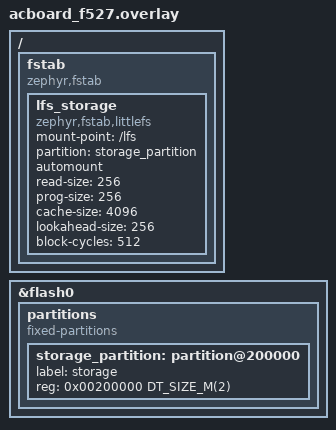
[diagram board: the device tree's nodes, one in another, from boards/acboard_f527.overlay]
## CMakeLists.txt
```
# SPDX-License-Identifier: Apache-2.0

cmake_minimum_required(VERSION 3.20.0)

find_package(Zephyr REQUIRED HINTS $ENV{ZEPHYR_BASE})
project(acboard_littlefs_config)

target_sources(app PRIVATE src/main.c)
```

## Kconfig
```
# Copyright (c) 2026
# SPDX-License-Identifier: Apache-2.0

mainmenu "ACBoard LittleFS config storage"

source "Kconfig.zephyr"
```

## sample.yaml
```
sample:
  name: ACBoard LittleFS config storage
common:
  platform_allow:
    - acboard_f527
  tags:
    - filesystem
    - flash
tests:
  sample.boards.acboard.littlefs_config:
    build_only: true
```

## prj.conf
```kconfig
CONFIG_FLASH=y
CONFIG_FLASH_MAP=y

CONFIG_FILE_SYSTEM=y
CONFIG_FILE_SYSTEM_LITTLEFS=y
CONFIG_FS_LITTLEFS_FSTAB_AUTOMOUNT=y

# The per-file cache heap is sized from this Kconfig; it must match the fstab
# cache-size (4096) or fs_open() fails with -ENOMEM.
CONFIG_FS_LITTLEFS_CACHE_SIZE=4096

CONFIG_PRINTK=y
CONFIG_LOG=y

# fs_dirent / LittleFS caches are sizeable.
CONFIG_MAIN_STACK_SIZE=4096
```

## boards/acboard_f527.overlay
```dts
/ {
	fstab {
		compatible = "zephyr,fstab";

		lfs_storage: lfs_storage {
			compatible = "zephyr,fstab,littlefs";
			mount-point = "/lfs";
			partition = <&storage_partition>;
			automount;
			/*
			 * Bank1 erase blocks are 128KB. read/prog/cache/lookahead
			 * must all divide the block size evenly.
			 */
			read-size = <256>;
			prog-size = <256>;
			cache-size = <4096>;
			lookahead-size = <256>;
			block-cycles = <512>;
		};
	};
};

/*
 * Bank1 (0x200000-0x3FFFFF, 2MB) is reserved as configuration storage. The
 * first erase block (128KB) is physically the group 4x16KB + 64KB, which sums
 * to exactly 128KB, so a uniform 128KB LittleFS block aligns across the whole
 * bank.
 */
&flash0 {
	partitions {
		compatible = "fixed-partitions";
		#address-cells = <1>;
		#size-cells = <1>;

		storage_partition: partition@200000 {
			label = "storage";
			reg = <0x00200000 DT_SIZE_M(2)>;
		};
	};
};
```

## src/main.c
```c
/*
 * Copyright (c) 2026
 * SPDX-License-Identifier: Apache-2.0
 *
 * Demonstrates LittleFS configuration storage on the GD32F527 Bank1 flash
 * (2MB) of ACBoard-F527. The filesystem is auto-mounted at /lfs by the fstab
 * entry. The sample keeps a persistent boot counter and a small key-value
 * config file to show that data survives resets and power cycles.
 */

#include <errno.h>
#include <stdint.h>
#include <stdio.h>
#include <string.h>

#include <zephyr/fs/fs.h>
#include <zephyr/kernel.h>
#include <zephyr/sys/printk.h>

#define MOUNT_POINT	"/lfs"
#define COUNTER_PATH	MOUNT_POINT "/boot_count"
#define CONFIG_PATH	MOUNT_POINT "/device.cfg"

static int read_boot_count(uint32_t *count)
{
	struct fs_file_t file;
	int ret;

	fs_file_t_init(&file);
	*count = 0U;

	ret = fs_open(&file, COUNTER_PATH, FS_O_CREATE | FS_O_RDWR);
	if (ret < 0) {
		printk("open %s failed: %d\n", COUNTER_PATH, ret);
		return ret;
	}

	ret = fs_read(&file, count, sizeof(*count));
	if (ret < 0) {
		printk("read boot count failed: %d\n", ret);
		(void)fs_close(&file);
		return ret;
	}
	if (ret < (int)sizeof(*count)) {
		/* Fresh file. */
		*count = 0U;
	}

	(void)fs_close(&file);
	return 0;
}

static int write_boot_count(uint32_t count)
{
	struct fs_file_t file;
	int ret;

	fs_file_t_init(&file);

	ret = fs_open(&file, COUNTER_PATH, FS_O_CREATE | FS_O_RDWR);
	if (ret < 0) {
		return ret;
	}

	ret = fs_seek(&file, 0, FS_SEEK_SET);
	if (ret == 0) {
		ret = fs_write(&file, &count, sizeof(count));
	}

	(void)fs_close(&file);
	return (ret < 0) ? ret : 0;
}

static int store_config(const char *text)
{
	struct fs_file_t file;
	int ret;

	fs_file_t_init(&file);

	ret = fs_open(&file, CONFIG_PATH, FS_O_CREATE | FS_O_WRITE | FS_O_TRUNC);
	if (ret < 0) {
		return ret;
	}

	ret = fs_write(&file, text, strlen(text));
	(void)fs_close(&file);
	return (ret < 0) ? ret : 0;
}

static int load_config(char *buf, size_t buf_size)
{
	struct fs_file_t file;
	int ret;

	fs_file_t_init(&file);

	ret = fs_open(&file, CONFIG_PATH, FS_O_READ);
	if (ret < 0) {
		return ret;
	}

	ret = fs_read(&file, buf, buf_size - 1U);
	if (ret >= 0) {
		buf[ret] = '\0';
	}
	(void)fs_close(&file);
	return ret;
}

int main(void)
{
	struct fs_statvfs stat;
	char config[64];
	uint32_t boot_count;
	int ret;

	printk("\nACBoard GD32F527 LittleFS config storage (Bank1, 2MB)\n");

	ret = fs_statvfs(MOUNT_POINT, &stat);
	if (ret < 0) {
		printk("%s not mounted: %d\n", MOUNT_POINT, ret);
		return 0;
	}
	printk("%s mounted: block size %lu, blocks %lu, free %lu\n", MOUNT_POINT,
	       stat.f_bsize, stat.f_blocks, stat.f_bfree);

	ret = read_boot_count(&boot_count);
	if (ret < 0) {
		return 0;
	}
	boot_count++;
	printk("boot count: %u\n", boot_count);

	ret = write_boot_count(boot_count);
	if (ret < 0) {
		printk("persist boot count failed: %d\n", ret);
		return 0;
	}

	/* On the first boot store an example device config; afterwards read it
	 * back to prove persistence.
	 */
	struct fs_dirent ent;

	ret = fs_stat(CONFIG_PATH, &ent);
	if (ret == -ENOENT) {
		const char *initial = "name=ID.UNYX;pnc=1";

		printk("no config yet, writing defaults\n");
		ret = store_config(initial);
		if (ret < 0) {
			printk("store config failed: %d\n", ret);
			return 0;
		}
		strcpy(config, initial);
	} else if (ret == 0) {
		ret = load_config(config, sizeof(config));
		if (ret < 0) {
			printk("load config failed: %d\n", ret);
			return 0;
		}
	} else {
		printk("stat config failed: %d\n", ret);
		return 0;
	}
	printk("config: %s\n", config);

	printk("done -- reset the board to see the boot count increment\n");
	return 0;
}
```
